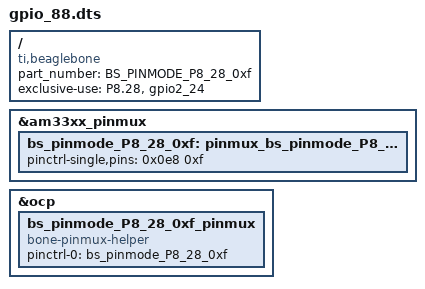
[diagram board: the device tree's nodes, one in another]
/dts-v1/;
/plugin/;

/{
    compatible = "ti,beaglebone", "ti,beaglebone-black";
        part_number = "BS_PINMODE_P8_28_0xf";

    exclusive-use =
            "P8.28",
	            "gpio2_24";

    fragment@0 {
            target = <&am33xx_pinmux>;
	            __overlay__ {
		                bs_pinmode_P8_28_0xf: pinmux_bs_pinmode_P8_28_0xf {
				                pinctrl-single,pins = <0x0e8 0xf>;
						            };
							            };
								        };

    fragment@1 {
            target = <&ocp>;
	            __overlay__ {
		                bs_pinmode_P8_28_0xf_pinmux {
				                compatible = "bone-pinmux-helper";
						                status = "okay";
								                pinctrl-names = "default";
										                pinctrl-0 = <&bs_pinmode_P8_28_0xf>;
												            };
													            };
														        };
															};
															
